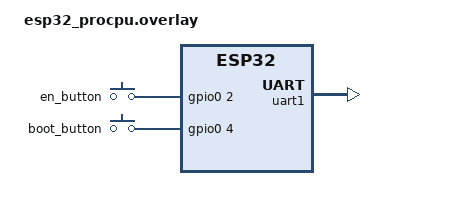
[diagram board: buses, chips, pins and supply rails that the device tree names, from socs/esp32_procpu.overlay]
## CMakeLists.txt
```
# SPDX-FileCopyrightText: 2026 Espressif Systems (Shanghai) CO LTD
# SPDX-License-Identifier: Apache-2.0

cmake_minimum_required(VERSION 3.22)

find_package(Zephyr REQUIRED HINTS $ENV{ZEPHYR_BASE})
project(zephyr_flasher)

target_sources(app PRIVATE
  ../common/example_common.c
  )

target_include_directories(app PRIVATE
  include
  ../common
  )

zephyr_linker_sources(SECTIONS sections-rom.ld)
include(${CMAKE_SOURCE_DIR}/include/bin_images_sections.cmake)
create_resources(${CMAKE_SOURCE_DIR}/target-firmware ${CMAKE_BINARY_DIR}/target_firmware_data.c)
set_property(SOURCE ${CMAKE_BINARY_DIR}/target_firmware_data.c PROPERTY GENERATED 1)

target_sources(app PRIVATE ${CMAKE_BINARY_DIR}/target_firmware_data.c)
target_sources(app PRIVATE src/main.c)

if(CONFIG_ESP_SERIAL_FLASHER_SHELL)
  target_sources(app PRIVATE src/shell.c)
endif()
```

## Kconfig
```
menu "Example config"

source "Kconfig.zephyr"

config ESP_SERIAL_FLASHER_SHELL
    bool "ESP Serial Flasher shell user interface"
    select SHELL
    help
      This option enables the user interactive SHELL
      in Zephyr example application

endmenu
```

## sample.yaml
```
sample:
  description: ESP Serial Flasher sample code
  name: zephyr_flasher
tests:
  sample.esp_flasher.zephyr_example:
    platform_allow: esp32
    tags: esp32
```

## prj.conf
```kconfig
CONFIG_ESP_SERIAL_FLASHER=y
#CONFIG_SERIAL_FLASHER_LOG_LEVEL_DEBUG=y

CONFIG_LOG=y
CONFIG_LOG_BACKEND_SHOW_COLOR=y
CONFIG_LOG_DEFAULT_LEVEL=2

CONFIG_GPIO=y
CONFIG_SERIAL=y
CONFIG_CONSOLE=y
CONFIG_CONSOLE_GETCHAR=y
```

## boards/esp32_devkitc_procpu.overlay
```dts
/*
 * SPDX-FileCopyrightText: 2026 Espressif Systems (Shanghai) CO LTD
 *
 * SPDX-License-Identifier: Apache-2.0
 */

/ {
	esp_loader0: esp_loader {
		compatible = "espressif,esp-loader";
		uart = <&uart1>;
		default-baudrate = <115200>;
		higher-baudrate = <230400>;
		reset-gpios = <&gpio0 25 (GPIO_PULL_UP | GPIO_ACTIVE_LOW)>;
		boot-gpios = <&gpio0 26 (GPIO_PULL_UP | GPIO_ACTIVE_LOW)>;
		sync-timeout-ms = <100>;
		num-trials = <10>;
		status = "disabled";
	};

	chosen {
		zephyr,esp-loader = &esp_loader0;
	};
};

&pinctrl {
	uart1_example: uart1_example {
		group1 {
			pinmux = <UART1_TX_GPIO4>;
			output-high;
		};
		group2 {
			pinmux = <UART1_RX_GPIO5>;
			bias-pull-up;
		};
	};
};

&uart1 {
	pinctrl-0 = <&uart1_example>;
	pinctrl-names = "default";
	current-speed = <115200>;
	status = "okay";
};

&esp_loader0 {
	status = "okay";
};
```

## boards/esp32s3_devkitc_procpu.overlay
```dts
/*
 * SPDX-FileCopyrightText: 2026 Espressif Systems (Shanghai) CO LTD
 *
 * SPDX-License-Identifier: Apache-2.0
 */

/ {
	esp_loader0: esp_loader {
		compatible = "espressif,esp-loader";
		uart = <&uart1>;
		default-baudrate = <115200>;
		higher-baudrate = <230400>;
		reset-gpios = <&gpio0 7 (GPIO_PULL_UP | GPIO_ACTIVE_LOW)>;
		boot-gpios = <&gpio0 8 (GPIO_PULL_UP | GPIO_ACTIVE_LOW)>;
		sync-timeout-ms = <100>;
		num-trials = <10>;
		status = "disabled";
	};

	chosen {
		zephyr,esp-loader = &esp_loader0;
	};
};

&pinctrl {
	uart1_example: uart1_example {
		group1 {
			pinmux = <UART1_TX_GPIO18>;
			output-high;
		};
		group2 {
			pinmux = <UART1_RX_GPIO17>;
			bias-pull-up;
		};
	};
};

&uart1 {
	pinctrl-0 = <&uart1_example>;
	pinctrl-names = "default";
	current-speed = <115200>;
	status = "okay";
};

&esp_loader0 {
	status = "okay";
};
```

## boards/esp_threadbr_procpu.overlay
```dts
/*
 * SPDX-FileCopyrightText: 2026 Espressif Systems (Shanghai) CO LTD
 *
 * SPDX-License-Identifier: Apache-2.0
 */

/ {
	esp_loader0: esp_loader {
		compatible = "espressif,esp-loader";
		uart = <&uart1>;
		default-baudrate = <115200>;
		higher-baudrate = <230400>;
		reset-gpios = <&gpio0 7 (GPIO_PULL_UP | GPIO_ACTIVE_LOW)>;
		boot-gpios = <&gpio0 8 (GPIO_PULL_UP | GPIO_ACTIVE_LOW)>;
		sync-timeout-ms = <100>;
		num-trials = <10>;
		status = "disabled";
	};

	chosen {
		zephyr,esp-loader = &esp_loader0;
	};
};

&pinctrl {
	uart1_example: uart1_example {
		group1 {
			pinmux = <UART1_TX_GPIO18>;
			output-high;
		};
		group2 {
			pinmux = <UART1_RX_GPIO17>;
			bias-pull-up;
		};
	};
};

&uart1 {
	status = "okay";
	current-speed = <115200>;
	pinctrl-0 = <&uart1_example>;
	pinctrl-names = "default";
};

&esp_loader0 {
	status = "okay";
};
```

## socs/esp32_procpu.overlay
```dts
/*
 * Copyright (c) 2024 Espressif Systems (Shanghai) Co., Ltd.
 *
 * SPDX-License-Identifier: Apache-2.0
 */

/ {
	aliases {
		en = &en_button;
		boot = &boot_button;
		uart = &uart1;
	};

	gpio_keys {
		compatible = "gpio-keys";
		en_button: en_button {
			gpios = <&gpio0 2 (GPIO_PULL_UP | GPIO_ACTIVE_HIGH)>;
		};
		boot_button: boot_button {
			gpios = <&gpio0 4 (GPIO_PULL_UP | GPIO_ACTIVE_HIGH)>;
		};
	};
};

&uart1 {
	status = "okay";
};
```

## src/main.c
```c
/*
 * SPDX-FileCopyrightText: 2026 Espressif Systems (Shanghai) CO LTD
 *
 * SPDX-License-Identifier: Apache-2.0
 */

#include <zephyr/kernel.h>
#include <zephyr/device.h>
#include <zephyr/drivers/uart.h>
#include <esp_loader.h>
#include <esp_loader_io.h>
#include <bin_image.h>
#include <zephyr_port.h>

#include <zephyr/logging/log.h>
LOG_MODULE_REGISTER(main);

const struct device *dev = DEVICE_DT_GET(DT_CHOSEN(zephyr_esp_loader));

#ifndef CONFIG_ESP_SERIAL_FLASHER_SHELL
static uint8_t buf[128];
#endif /* CONFIG_ESP_SERIAL_FLASHER_SHELL */

static const uint32_t boot_offset[] = {
    [ESP8266_CHIP] = 0x0,
    [ESP32_CHIP]   = 0x1000,
    [ESP32S2_CHIP] = 0x1000,
    [ESP32C3_CHIP] = 0x0,
    [ESP32S3_CHIP] = 0x0,
    [ESP32C2_CHIP] = 0x0,
    [ESP32C5_CHIP] = 0x2000,
    [ESP32H2_CHIP] = 0x0,
    [ESP32C6_CHIP] = 0x0,
    [ESP32P4_CHIP] = 0x2000,
    [ESP32C61_CHIP] = 0x0,
    [ESP32S31_CHIP] = 0x2000,
    [ESP32H21_CHIP] = 0x0,
    [ESP32H4_CHIP] = 0x2000
};

/* If someone adds a new chip but forgets to update the array, compilation FAILS */
_Static_assert(sizeof(boot_offset) / sizeof(boot_offset[0]) == ESP_MAX_CHIP,
               "boot_offset array size mismatch! "
               "If you added a new chip to target_chip_t, you MUST add its address to boot_offset[]");

static const char *target_name[] = {
    [ESP8266_CHIP] = "ESP8266",
    [ESP32_CHIP]   = "ESP32",
    [ESP32S2_CHIP] = "ESP32-S2",
    [ESP32C3_CHIP] = "ESP32-C3",
    [ESP32S3_CHIP] = "ESP32-S3",
    [ESP32C2_CHIP] = "ESP32-C2",
    [ESP32C5_CHIP] = "ESP32-C5",
    [ESP32H2_CHIP] = "ESP32-H2",
    [ESP32C6_CHIP] = "ESP32-C6",
    [ESP32P4_CHIP] = "ESP32-P4",
    [ESP32C61_CHIP] = "ESP32-C61",
    [ESP32S31_CHIP] = "ESP32-S31",
    [ESP32H21_CHIP] = "ESP32-H21",
    [ESP32H4_CHIP] = "ESP32-H4",
    [ESP_UNKNOWN_CHIP] = "Unknown"
};

uint32_t get_boot_offset(target_chip_t chip)
{
    if (chip >= ESP_MAX_CHIP) {
        return 0;
    }
    return boot_offset[chip];
}

const char *get_target_name(target_chip_t chip)
{
    return target_name[chip];
}

int install_image(esp_loader_t *loader, const void *bin, size_t size, size_t address)
{
    esp_loader_error_t err;
    static uint8_t payload[1024];
    const uint8_t *bin_addr = bin;

    esp_loader_flash_cfg_t flash = {
        .offset = address,
        .image_size = size,
        .block_size = sizeof(payload),
    };

    printf("Erasing flash\n");
    err = esp_loader_flash_start(loader, &flash);
    if (err != ESP_LOADER_SUCCESS) {
        LOG_ERR("Erasing flash failed with error: %d", err);

        if (err == ESP_LOADER_ERROR_INVALID_PARAM) {
            LOG_ERR("If using Secure Download Mode, double check that the specified "
                    "target flash size is correct.");
        }
        return err;
    }

    printf("Start programming\n");

    size_t written = 0;
    size_t binary_size = size;

    while (size > 0) {
        size_t to_write = MIN(size, sizeof(payload));

        memcpy(payload, bin_addr, to_write);
        err = esp_loader_flash_write(loader, &flash, payload, to_write);

        if (err != ESP_LOADER_SUCCESS) {
            LOG_ERR("Packet could not be written! Error %d", err);
            return err;
        }
        size -= to_write;
        bin_addr += to_write;
        written += to_write;
        int progress = (int)(((float)written / binary_size) * 100);
        printf("\r%d %%", progress);
    }
    printf("\nFinished programming\n");

    err = esp_loader_flash_finish(loader, &flash);
    if (err == ESP_LOADER_ERROR_INVALID_MD5) {
        printf("MD5 does not match. Flash verification failed.\n");
        return err;
    } else if (err != ESP_LOADER_SUCCESS) {
        LOG_ERR("Flash finish failed with error: %d", err);
        return err;
    }

    if (!flash.skip_verify) {
        printf("Flash verified\n");
    }

    return 0;
}

int main(void)
{
#if !defined(CONFIG_ESP_SERIAL_FLASHER_SHELL)
    target_chip_t chip_id;
    uint32_t offset, size;
    esp_loader_t *loader;
    const esp_loader_config_t *conf;
    const esp_loader_connect_args_t *carg;

    loader = esp_loader_from_device(dev);
    conf = esp_loader_config_from_device(dev);
    carg = esp_loader_connect_args_from_device(dev);

    printf("Running ESP Flasher from Zephyr\r\n");

    LOG_INF("Running ESP Serial Flasher instance");
    LOG_INF("Transmission default speed: %d higher speed: %d",
            conf->baud_rate, conf->baud_rate_high);

    if (esp_loader_connect(loader, (esp_loader_connect_args_t *) carg) != ESP_LOADER_SUCCESS) {
        LOG_ERR("Could not connect target");
        return -EIO;
    }

    printf("\nConnected to target\n");

    LOG_INF("Setting higher transmission rate");

    if (conf->baud_rate_high) {
        if (esp_loader_change_transmission_rate(loader, conf->baud_rate_high) != ESP_LOADER_SUCCESS) {
            LOG_ERR("Unable to change transmission rate on target.");
            return -EIO;
        }
        printf("Transmission rate changed\n");
    }

    /*  Fetch chip information */
    chip_id = esp_loader_get_target(loader);
    offset = get_boot_offset(chip_id);
    LOG_INF("Target name: %s (id: %d), ROM boot offset: 0x%x",
            get_target_name(chip_id), chip_id, offset);

    if (esp_loader_flash_detect_size(loader, &size) != ESP_LOADER_SUCCESS) {
        LOG_ERR("Could not read target flash size!\n");
        return -1;
    }
    LOG_INF("Target flash size [B]: %u (%d MB)", size, size / 1024 / 1024);

    if (esp_loader_flash_read(loader, buf, offset, sizeof(buf)) != ESP_LOADER_SUCCESS) {
        LOG_ERR("Failed reading flash starting at address 0x%x", offset);
        return -1;
    }
    LOG_INF("Reading image header from boot offset:");
    LOG_HEXDUMP_INF(buf, 16, "ROM bootloader header:");

    if (buf[0] == 0xe9) {
        LOG_INF("Boot vector installed");
    } else {
        LOG_INF("Target chip not bootable!");
    }

    /* Flash images provided locally */
    LOG_INF("Installing target with available images:");

    STRUCT_SECTION_FOREACH(bin_image, t) {
        printf("Loading '%s' (size %d B, at 0x%x)\n", t->fname, t->size, t->offset);
        install_image(loader, t->data, t->size, t->offset);
    }
    printf("\nDONE\n");

    if (esp_loader_host_baudrate(loader, conf->baud_rate) != ESP_LOADER_SUCCESS) {
        LOG_ERR("Failed to set default host baudrate");
        return -1;
    }
    k_msleep(200);

    esp_loader_reset_target(loader);
    LOG_INF("Resetting target");

    printf("**********************************************\n");
    printf("*** Logs below are printed from target ... ***\n");
    printf("**********************************************\n");

    char c;
    while (1) {
        if (uart_poll_in(conf->uart_dev, &c) == 0) {
            printf("%c", c);
        } else {
            k_yield();
        }
    }
#else
    printf("Type 'esf help' to show serial flasher shell command options");
#endif

    return 0;
}
```

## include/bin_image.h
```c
/*
 * SPDX-FileCopyrightText: 2026 Espressif Systems (Shanghai) CO LTD
 *
 * SPDX-License-Identifier: Apache-2.0
 */

#pragma once

#include <stdint.h>
#include <zephyr/sys/iterable_sections.h>

struct bin_image {
    const uint8_t *data;
    uint32_t offset;
    uint32_t size;
    const char *md5;
    const char *fname;
};

#define DEFINE_IMAGE(name, _d, _o, _s, _m, _f) \
         STRUCT_SECTION_ITERABLE(bin_image, name) = { \
                 .data = _d, \
                 .offset = _o, \
                 .size = _s, \
                 .md5 = _m, \
                 .fname = _f, \
         }
```

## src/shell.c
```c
/*
 * SPDX-FileCopyrightText: 2026 Espressif Systems (Shanghai) CO LTD
 *
 * SPDX-License-Identifier: Apache-2.0
 */

#include <stdlib.h>
#include <zephyr/devicetree.h>
#include <zephyr/shell/shell.h>
#include <zephyr/drivers/uart.h>
#include <esp_loader.h>
#include <esp_loader_io.h>
#include <bin_image.h>
#include <zephyr_port.h>

static esp_loader_t *loader;
static const esp_loader_config_t *conf;
static const esp_loader_connect_args_t *carg;
static bool connected;

/* Helper functions from the main module */
const char *get_target_name(target_chip_t chip);
uint32_t get_boot_offset(target_chip_t chip);
int install_image(esp_loader_t *loader, const void *bin, size_t size, size_t address);

static int cmd_esf_connect_rom(const struct shell *sh, size_t argc, char **argv)
{
    ARG_UNUSED(argc);
    ARG_UNUSED(argv);

    if (esp_loader_connect(loader, (esp_loader_connect_args_t *)carg) != ESP_LOADER_SUCCESS) {
        shell_error(sh, "Failed to connect ROM");
        return -1;
    }
    connected = true;

    shell_print(sh, "ROM connected at %d bps", conf->baud_rate);

    return 0;
}

static int cmd_esf_connect_stub(const struct shell *sh, size_t argc, char **argv)
{
    ARG_UNUSED(argc);
    ARG_UNUSED(argv);

    if (esp_loader_connect_with_stub(loader, (esp_loader_connect_args_t *)carg) != ESP_LOADER_SUCCESS) {
        shell_error(sh, "Failed to connect STUB");
        return -1;
    }
    connected = true;

    shell_print(sh, "STUB connected at %d", conf->baud_rate);

    return 0;
}

SHELL_STATIC_SUBCMD_SET_CREATE(sub_esf_connect,
                               SHELL_CMD_ARG(rom, NULL, "Connect /w ROM functions", cmd_esf_connect_rom, 1, 0),
                               SHELL_CMD_ARG(stub, NULL, "Connect /w STUB functions", cmd_esf_connect_stub, 1, 0),
                               SHELL_SUBCMD_SET_END);

static int cmd_esf_reset(const struct shell *sh, size_t argc, char **argv)
{
    ARG_UNUSED(argc);
    ARG_UNUSED(argv);

    if (!connected) {
        shell_error(sh, "Target hasn't been connected");
        return -1;
    }
    esp_loader_reset_target(loader);
    connected = false;

    shell_print(sh, "Target reset done");

    return 0;
}

static int cmd_esf_target_info(const struct shell *sh, size_t argc, char **argv)
{
    esp_loader_target_security_info_t info;
    target_chip_t id;
    uint32_t size, offset;
    uint8_t mac[10];
    const char *name;

    if (!connected) {
        shell_error(sh, "Target not connected");
        return -1;
    }
    id = esp_loader_get_target(loader);
    name = get_target_name(id);
    offset = get_boot_offset(id);

    if (esp_loader_read_mac(loader, mac)) {
        memset(mac, 0, sizeof(mac));
    }

    if (esp_loader_flash_detect_size(loader, &size)) {
        shell_error(sh, "Failed to detect flash size");
        return -1;
    }

    if (esp_loader_get_security_info(loader, &info)) {
        shell_error(sh, "Failed to read security information");
        return -1;
    }

    if (argc > 1) {
        if (strcmp(argv[1], "chip") == 0) {
            shell_print(sh, "%s", name);
            return 0;
        }
        if (strcmp(argv[1], "flash") == 0) {
            shell_print(sh, "%d MB", size / 1024 / 1024);
            return 0;
        }
        if (strcmp(argv[1], "boot") == 0) {
            shell_print(sh, "0x%x", offset);
            return 0;
        }
    }
    shell_print(sh, "%s, boot offset: 0x%x", name, offset);
    shell_print(sh, "Flash size: %d (%d MB)", size, size / 1024 / 1024);
    if (!mac[0] && !mac[1] && !mac[2]) {
        shell_error(sh, "MAC read error");
    } else {
        shell_print(sh, "MAC %x:%x:%x:%x:%x:%x  %x:%x", mac[0], mac[1], mac[2],
                    mac[3], mac[4], mac[5], mac[6], mac[7]);
    }
    shell_print(sh, "Target chip : %d", info.target_chip);
    shell_print(sh, "ECO version : %X", info.eco_version);
    shell_print(sh, "USB : %s", info.usb_disabled ? "disabled" : "enabled");
    shell_print(sh, "JTAG software : %s",
                info.jtag_software_disabled ? "disabled" : "enabled");
    shell_print(sh, "JTAG hardware : %s",
                info.jtag_hardware_disabled ? "disabled" : "enabled");
    shell_print(sh, "Flash encryption : %s",
                info.flash_encryption_enabled ? "enabled" : "disabled");
    shell_print(sh, "Secure boot : %s", info.secure_boot_enabled ? "enabled" : "disabled");
    for (int i = 0; i < 3; i++) {
        shell_print(sh, "Secure boot revoked keys.[%d] %s", i,
                    info.secure_boot_revoked_keys[i] ? "enabled" : "disabled");
    }
    shell_print(sh, "Secure boot aggressive revoke : %s",
                info.secure_boot_aggressive_revoke_enabled ? "enabled" : "disabled");
    shell_print(sh, "Secure download mode : %s",
                info.secure_download_mode_enabled ? "enabled" : "disabled");
    shell_print(sh, "Dcache in UART download : %s",
                info.dcache_in_uart_download_disabled ? "disabled" : "enabled");
    shell_print(sh, "Icache in UART download : %s",
                info.icache_in_uart_download_disabled ? "disabled" : "enabled");

    return 0;
}

static int cmd_esf_flash_read(const struct shell *sh, size_t argc, char **argv)
{
    uint8_t buf[128];
    uint32_t addr = 0;
    uint32_t size = 1;

    if (!connected) {
        shell_error(sh, "Target not connected");
        return -1;
    }

    if (argc > 1) {
        addr = strtoul(argv[1], NULL, 16);
    }
    if (argc > 2) {
        size = strtoul(argv[2], NULL, 16);
    }
    shell_print(sh, "Reading %d bytes from offset 0x%x", size, addr);

    while (size > 0) {
        size_t to_read = MIN(size, sizeof(buf));

        if (esp_loader_flash_read(loader, buf, addr, to_read) != ESP_LOADER_SUCCESS) {
            shell_error(sh, "Failed to read flash");
            return -1;
        }
        shell_hexdump_line(sh, addr, buf, to_read);
        size -= to_read;
        addr += to_read;
    }

    return 0;
}

static int cmd_esf_img_install(const struct shell *sh, size_t argc, char **argv)
{
    int i = 0;
    int selected = -1;

    if (!connected) {
        shell_error(sh, "Target not connected");
        return -1;
    }

    if (argc > 1) {
        selected = strtoul((argv)[1], NULL, 10);
    }

    STRUCT_SECTION_FOREACH(bin_image, t) {
        if (selected >= 0) {
            if (selected == i++) {
                shell_print(sh, "Installing image '%s' at offset 0x%x", t->fname, t->offset);
                install_image(loader, t->data, t->size, t->offset);
            }
        } else {
            shell_print(sh, "Installing image '%s' at offset 0x%x", t->fname, t->offset);
            install_image(loader, t->data, t->size, t->offset);
        }
    }

    shell_print(sh, "Done");

    return 0;
}

static int cmd_esf_flash_erase(const struct shell *sh, size_t argc, char **argv)
{
    uint32_t offset, size;

    if (!connected) {
        shell_print(sh, "Target not connected");
        return -1;
    }

    if (argc > 1) {
        offset = strtoul(argv[1], NULL, 16);
        if (argc > 2) {
            size = strtoul(argv[2], NULL, 16);
        } else {
            size = 1;
        }
        if (esp_loader_flash_erase_region(loader, offset, size)) {
            shell_print(sh, "Failed to erase region");
            return -1;
        }
    } else {
        if (esp_loader_flash_erase(loader)) {
            shell_print(sh, "Failed to erase whole flash");
            return -1;
        }
    }
    return 0;
}

SHELL_STATIC_SUBCMD_SET_CREATE(sub_esf_flash,
                               SHELL_CMD_ARG(read, NULL, "<address> [<byte count>]", cmd_esf_flash_read, 2, 1),
                               SHELL_CMD_ARG(image, NULL, "[<img_index>], OR install all", cmd_esf_img_install, 1, 1),
                               SHELL_CMD_ARG(erase, NULL, "[<address> [<size>]]", cmd_esf_flash_erase, 1, 2),
                               SHELL_SUBCMD_SET_END);

static int cmd_esf_register_read(const struct shell *sh, size_t argc, char **argv)
{
    uint32_t reg = 0;
    uint32_t val = 0;

    if (!connected) {
        shell_print(sh, "Target not connected");
        return -1;
    }

    if (argc > 1) {
        reg = strtoul((argv)[1], NULL, 16);
    }
    if (esp_loader_read_register(loader, reg, &val)) {
        shell_print(sh, "Failed to read register");
        return -1;
    }
    shell_print(sh, "0x%x = 0x%x", reg, val);

    return 0;
}

static int cmd_esf_register_write(const struct shell *sh, size_t argc, char **argv)
{
    uint32_t reg = 0;
    uint32_t val = 0;

    if (!connected) {
        shell_print(sh, "Target not connected");
        return -1;
    }

    if (argc > 1) {
        reg = strtoul((argv)[1], NULL, 16);
    }
    if (argc > 2) {
        val = strtoul((argv)[2], NULL, 16);
    }
    if (esp_loader_write_register(loader, reg, val)) {
        shell_print(sh, "Failed to write to register 0x%x", reg);
        return -1;
    }
    return 0;
}

SHELL_STATIC_SUBCMD_SET_CREATE(sub_esf_register,
                               SHELL_CMD_ARG(read, NULL, "<register>", cmd_esf_register_read, 2, 0),
                               SHELL_CMD_ARG(write, NULL, "<register> [value]", cmd_esf_register_write, 3, 0),
                               SHELL_SUBCMD_SET_END);

static int cmd_esf_speed_default(const struct shell *sh, size_t argc, char **argv)
{
    ARG_UNUSED(argc);
    ARG_UNUSED(argv);
    esp_loader_error_t err;

    if (!connected) {
        shell_print(sh, "Target not connected");
        return -1;
    }

    err = esp_loader_change_transmission_rate(loader, conf->baud_rate);
    if (err != ESP_LOADER_SUCCESS) {
        shell_print(sh, "Failed to set transmission rate to %d", conf->baud_rate);
        return -1;
    }
    shell_print(sh, "Transmission rate set to %d", conf->baud_rate);

    return 0;
}

static int cmd_esf_speed_higher(const struct shell *sh, size_t argc, char **argv)
{
    ARG_UNUSED(argc);
    ARG_UNUSED(argv);
    esp_loader_error_t err;

    if (!connected) {
        shell_print(sh, "Target not connected");
        return -1;
    }
    if (!conf->baud_rate_high) {
        shell_print(sh, "Higher transmission rate not configured");
        return -1;
    }
    err = esp_loader_change_transmission_rate(loader, conf->baud_rate_high);
    if (err != ESP_LOADER_SUCCESS) {
        shell_print(sh, "Failed to set transmission rate to %d", conf->baud_rate_high);
        return -1;
    }
    shell_print(sh, "Transmission rate set to %d", conf->baud_rate_high);

    return 0;
}

SHELL_STATIC_SUBCMD_SET_CREATE(sub_esf_speed,
                               SHELL_CMD_ARG(default, NULL, "Default speed", cmd_esf_speed_default, 0, 0),
                               SHELL_CMD_ARG(higher, NULL, "Higher speed", cmd_esf_speed_higher, 0, 0),
                               SHELL_SUBCMD_SET_END);

static int cmd_esf_images(const struct shell *sh, size_t argc, char **argv)
{
    ARG_UNUSED(argc);
    ARG_UNUSED(argv);

    int i = 0;

    STRUCT_SECTION_FOREACH(bin_image, t) {
        shell_print(sh, "%d: md5: '%s' length: %d offset: 0x%x name: '%s'", i++,
                    t->md5, t->size, t->offset, t->fname);
    }
    return 0;
}

SHELL_STATIC_SUBCMD_SET_CREATE(sub_esf,
                               SHELL_CMD(reset, NULL, "Reset target", cmd_esf_reset),
                               SHELL_CMD(info, NULL, "[chip|flash|boot]", cmd_esf_target_info),
                               SHELL_CMD(images, NULL, "List available images", cmd_esf_images),
                               SHELL_CMD(connect, &sub_esf_connect, "Connect target", NULL),
                               SHELL_CMD(speed, &sub_esf_speed, "Change transmission speed", NULL),
                               SHELL_CMD(flash, &sub_esf_flash, "Flash operations", NULL),
                               SHELL_CMD(register, &sub_esf_register, "Register operations", NULL),
                               SHELL_SUBCMD_SET_END);

SHELL_CMD_REGISTER(esf, &sub_esf, "ESP Serial Flasher commands", NULL);

static const struct device *dev = DEVICE_DT_GET(DT_CHOSEN(zephyr_esp_loader));

static int esp_loader_init_default(void)
{
    carg = esp_loader_connect_args_from_device(dev);
    conf = esp_loader_config_from_device(dev);
    loader = esp_loader_from_device(dev);
    connected = false;

    return 0;
}

SYS_INIT(esp_loader_init_default, APPLICATION, CONFIG_APPLICATION_INIT_PRIORITY);
```
